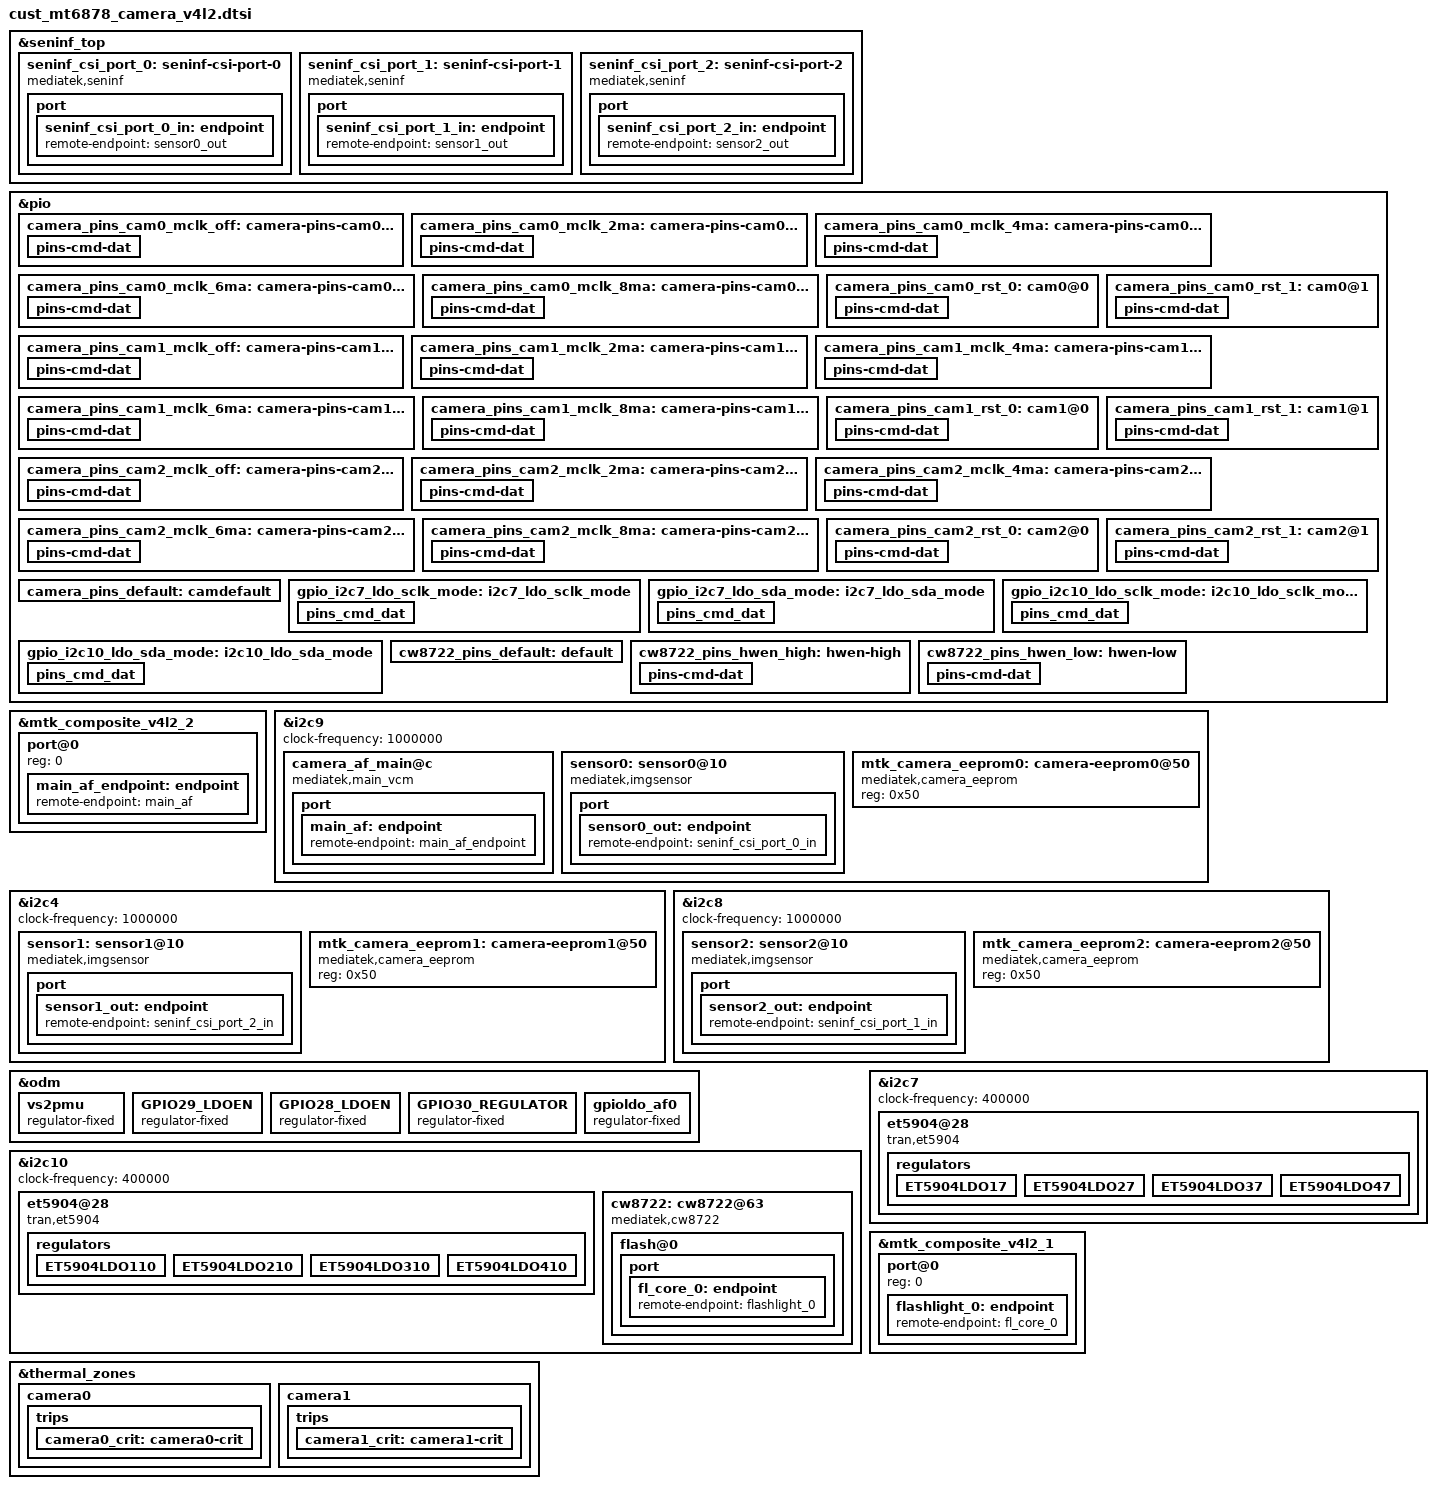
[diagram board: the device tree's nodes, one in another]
// SPDX-License-Identifier: GPL-2.0
/* Copyright (c) 2020 MediaTek Inc. */
#include <dt-bindings/clock/mt6878-clk.h>

&seninf_top {
		seninf_csi_port_0: seninf-csi-port-0 {
			compatible = "mediatek,seninf";
			csi-port = "0";
			dphy-settle-delay-dt = <17>;
			nvmem-cells = <&csi_efuse0>;
			nvmem-cell-names = "rg_csi";
			port {
				seninf_csi_port_0_in: endpoint {
					remote-endpoint = <&sensor0_out>;
				};
			};
		};

		seninf_csi_port_1: seninf-csi-port-1 {
			compatible = "mediatek,seninf";
			csi-port = "2";
			hs-trail-parameter = <0x20>;
			nvmem-cells = <&csi_efuse1>;
			nvmem-cell-names = "rg_csi";
			port {
				seninf_csi_port_1_in: endpoint {
					remote-endpoint = <&sensor1_out>;
				};
			};
		};
		seninf_csi_port_2: seninf-csi-port-2 {
			compatible = "mediatek,seninf";
			csi-port = "1";
			hs-trail-parameter = <0x20>;
			nvmem-cells = <&csi_efuse2>;
			nvmem-cell-names = "rg_csi";
			port {
				seninf_csi_port_2_in: endpoint {
					remote-endpoint = <&sensor2_out>;
				};
			};
		};
};


/* CAMERA GPIO standardization */
&pio {
	camera_pins_cam0_mclk_off: camera-pins-cam0-mclk-off {
		pins-cmd-dat {
			pinmux = <PINMUX_GPIO93__FUNC_GPIO93>;
			drive-strength = <1>;
		};
	};
	camera_pins_cam0_mclk_2ma: camera-pins-cam0-mclk-2ma {
		pins-cmd-dat {
			pinmux = <PINMUX_GPIO93__FUNC_CMMCLK1>;
			drive-strength = <0>;
		};
	};
	camera_pins_cam0_mclk_4ma: camera-pins-cam0-mclk-4ma {
		pins-cmd-dat {
			pinmux = <PINMUX_GPIO93__FUNC_CMMCLK1>;
			drive-strength = <1>;
		};
	};
	camera_pins_cam0_mclk_6ma: camera-pins-cam0-mclk-6ma {
		pins-cmd-dat {
			pinmux = <PINMUX_GPIO93__FUNC_CMMCLK1>;
			drive-strength = <2>;
		};
	};
	camera_pins_cam0_mclk_8ma: camera-pins-cam0-mclk-8ma {
		pins-cmd-dat {
			pinmux = <PINMUX_GPIO93__FUNC_CMMCLK1>;
			drive-strength = <3>;
		};
	};
	camera_pins_cam0_rst_0: cam0@0 {
		pins-cmd-dat {
			pinmux = <PINMUX_GPIO25__FUNC_GPIO25>;
			slew-rate = <1>;
			output-low;
		};
	};
	camera_pins_cam0_rst_1: cam0@1 {
		pins-cmd-dat {
			pinmux = <PINMUX_GPIO25__FUNC_GPIO25>;
			slew-rate = <1>;
			output-high;
		};
	};
	
	camera_pins_cam1_mclk_off: camera-pins-cam1-mclk-off {
		pins-cmd-dat {
			pinmux = <PINMUX_GPIO96__FUNC_GPIO96>;
			drive-strength = <1>;
		};
	};
	camera_pins_cam1_mclk_2ma: camera-pins-cam1-mclk-2ma {
		pins-cmd-dat {
			pinmux = <PINMUX_GPIO96__FUNC_CMMCLK4>;
			drive-strength = <0>;
		};
	};
	camera_pins_cam1_mclk_4ma: camera-pins-cam1-mclk-4ma {
		pins-cmd-dat {
			pinmux = <PINMUX_GPIO96__FUNC_CMMCLK4>;
			drive-strength = <1>;
		};
	};
	camera_pins_cam1_mclk_6ma: camera-pins-cam1-mclk-6ma {
		pins-cmd-dat {
			pinmux = <PINMUX_GPIO96__FUNC_CMMCLK4>;
			drive-strength = <2>;
		};
	};
	camera_pins_cam1_mclk_8ma: camera-pins-cam1-mclk-8ma {
		pins-cmd-dat {
			pinmux = <PINMUX_GPIO96__FUNC_CMMCLK4>;
			drive-strength = <3>;
		};
	};
	camera_pins_cam1_rst_0: cam1@0 {
		pins-cmd-dat {
			pinmux = <PINMUX_GPIO24__FUNC_GPIO24>;
			slew-rate = <1>;
			output-low;
		};
	};
	camera_pins_cam1_rst_1: cam1@1 {
		pins-cmd-dat {
			pinmux = <PINMUX_GPIO24__FUNC_GPIO24>;
			slew-rate = <1>;
			output-high;
		};
	};
	camera_pins_cam2_mclk_off: camera-pins-cam2-mclk-off {
		pins-cmd-dat {
			pinmux = <PINMUX_GPIO94__FUNC_GPIO94>;
			drive-strength = <1>;
		};
	};
	camera_pins_cam2_mclk_2ma: camera-pins-cam2-mclk-2ma {
		pins-cmd-dat {
			pinmux = <PINMUX_GPIO94__FUNC_CMMCLK2>;
			drive-strength = <0>;
		};
	};
	camera_pins_cam2_mclk_4ma: camera-pins-cam2-mclk-4ma {
		pins-cmd-dat {
			pinmux = <PINMUX_GPIO94__FUNC_CMMCLK2>;
			drive-strength = <1>;
		};
	};
	camera_pins_cam2_mclk_6ma: camera-pins-cam2-mclk-6ma {
		pins-cmd-dat {
			pinmux = <PINMUX_GPIO94__FUNC_CMMCLK2>;
			drive-strength = <2>;
		};
	};
	camera_pins_cam2_mclk_8ma: camera-pins-cam2-mclk-8ma {
		pins-cmd-dat {
			pinmux = <PINMUX_GPIO94__FUNC_CMMCLK2>;
			drive-strength = <3>;
		};
	};
	camera_pins_cam2_rst_0: cam2@0 {
		pins-cmd-dat {
			pinmux = <PINMUX_GPIO26__FUNC_GPIO26>;
			slew-rate = <1>;
			output-low;
		};
	};
	camera_pins_cam2_rst_1: cam2@1 {
		pins-cmd-dat {
			pinmux = <PINMUX_GPIO26__FUNC_GPIO26>;
			slew-rate = <1>;
			output-high;
		};
	};

	camera_pins_default: camdefault {
	};
};
/* CAMERA GPIO end */

&mtk_composite_v4l2_2 {
	#address-cells = <1>;
	#size-cells = <0>;
	port@0 {
		reg = <0>;
		main_af_endpoint: endpoint {
			remote-endpoint = <&main_af>;
		};
	};
};

&i2c9 {
	status = "okay";
	clock-frequency = <1000000>;

	camera_af_main@c {
		compatible = "mediatek,main_vcm";
		reg = <0x0c>;
		vin-supply = <&gpioldo_af0>;
		port {
			main_af: endpoint {
				remote-endpoint = <&main_af_endpoint>;
			};
		};
	};

	sensor0: sensor0@10 {
		compatible = "mediatek,imgsensor";
		sensor-names = "imx682_mipi_raw";
		reg = <0x10>;
		#thermal-sensor-cells = <0>;
		sensor-matecodes = "imx682_17201926";
		pinctrl-names = "mclk_off",
				"mclk_2mA",
				"mclk_4mA",
				"mclk_6mA",
				"mclk_8mA",
				"rst_low",
				"rst_high";

		pinctrl-0 = <&camera_pins_cam0_mclk_off>;
		pinctrl-1 = <&camera_pins_cam0_mclk_2ma>;
		pinctrl-2 = <&camera_pins_cam0_mclk_4ma>;
		pinctrl-3 = <&camera_pins_cam0_mclk_6ma>;
		pinctrl-4 = <&camera_pins_cam0_mclk_8ma>;
		pinctrl-5 = <&camera_pins_cam0_rst_0>;
		pinctrl-6 = <&camera_pins_cam0_rst_1>;

		avdd-supply = <&ET5904LDO410>;
		dvdd-supply = <&ET5904LDO210>;
		dovdd-supply = <&mt6369_vant18>;
		avdd1-supply =<&GPIO30_REGULATOR>;

		clocks = <&topckgen_clk CLK_TOP_UVPLL192M_D32>,
			<&topckgen_clk CLK_TOP_UVPLL192M_D16>,
			<&topckgen_clk CLK_TOP_OSC_D20>,
			<&topckgen_clk CLK_TOP_UVPLL192M_D10>,
			<&topckgen_clk CLK_TOP_UVPLL192M_D8>,
			<&topckgen_clk CLK_TOP_TCK_26M_MX9>,
			<&topckgen_clk CLK_TOP_UNIVPLL_D6_D8>,
			<&topckgen_clk CLK_TOP_CAMTG2_SEL>;
		clock-names = "6", "12", "13", "19.2", "24", "26", "52", "mclk";


		status = "okay";
		port {
			sensor0_out: endpoint {
				remote-endpoint = <&seninf_csi_port_0_in>;
			};
		};
	};

	mtk_camera_eeprom0:camera-eeprom0@50 {
		compatible = "mediatek,camera_eeprom";
		reg = <0x50>;
		status = "okay";
	};
};
&pio {
	gpio_i2c7_ldo_sclk_mode: i2c7_ldo_sclk_mode {
		pins_cmd_dat {
			pinmux = <PINMUX_GPIO139__FUNC_SCL7>;
			drive-strength = <4>;
		};
	};

	gpio_i2c7_ldo_sda_mode: i2c7_ldo_sda_mode {
		pins_cmd_dat {
			pinmux = <PINMUX_GPIO140__FUNC_SDA7>;
			drive-strength = <4>;
		};
	};
	gpio_i2c10_ldo_sclk_mode: i2c10_ldo_sclk_mode {
		pins_cmd_dat {
			pinmux = <PINMUX_GPIO145__FUNC_SCL10>;
			drive-strength = <4>;
		};
	};

	gpio_i2c10_ldo_sda_mode: i2c10_ldo_sda_mode {
		pins_cmd_dat {
			pinmux = <PINMUX_GPIO146__FUNC_SDA10>;
			drive-strength = <4>;
		};
	};
};

&i2c4 {
	status = "okay";
	clock-frequency = <1000000>;

	sensor1: sensor1@10 {
		compatible = "mediatek,imgsensor";
		sensor-names = "gc13a0ff_mipi_raw";
		reg = <0x10>;
		sensor-matecodes = "gc13a0_17201930";
		#thermal-sensor-cells = <0>;

		pinctrl-names = "mclk_off",
				"mclk_2mA",
				"mclk_4mA",
				"mclk_6mA",
				"mclk_8mA",
				"rst_low",
				"rst_high";
		pinctrl-0 = <&camera_pins_cam1_mclk_off>;
		pinctrl-1 = <&camera_pins_cam1_mclk_2ma>;
		pinctrl-2 = <&camera_pins_cam1_mclk_4ma>;
		pinctrl-3 = <&camera_pins_cam1_mclk_6ma>;
		pinctrl-4 = <&camera_pins_cam1_mclk_8ma>;
		pinctrl-5 = <&camera_pins_cam1_rst_0>;
		pinctrl-6 = <&camera_pins_cam1_rst_1>;

		avdd-supply = <&ET5904LDO310>;
		dvdd-supply = <&ET5904LDO110>;
		dovdd-supply = <&mt6369_vant18>;

		clocks = <&topckgen_clk CLK_TOP_UVPLL192M_D32>,
			<&topckgen_clk CLK_TOP_UVPLL192M_D16>,
			<&topckgen_clk CLK_TOP_OSC_D20>,
			<&topckgen_clk CLK_TOP_UVPLL192M_D10>,
			<&topckgen_clk CLK_TOP_UVPLL192M_D8>,
			<&topckgen_clk CLK_TOP_TCK_26M_MX9>,
			<&topckgen_clk CLK_TOP_UNIVPLL_D6_D8>,
			<&topckgen_clk CLK_TOP_CAMTG5_SEL>;
		clock-names = "6", "12", "13", "19.2", "24", "26", "52", "mclk";

		status = "okay";
		port {
			sensor1_out: endpoint {
				remote-endpoint = <&seninf_csi_port_2_in>;
			};
		};
	};

	mtk_camera_eeprom1:camera-eeprom1@50 {
		compatible = "mediatek,camera_eeprom";
		reg = <0x50>;
		status = "okay";
	};
};

&i2c8 {
	status = "okay";
	clock-frequency = <1000000>;
	#address-cells = <1>;
	#size-cells = <0>;

	sensor2: sensor2@10 {
		compatible = "mediatek,imgsensor";
		sensor-names = "gc02m3macro_mipi_raw";
		sensor-matecodes = "gc02m3_17201867";
		reg = <0x10>;
		#thermal-sensor-cells = <0>;

		pinctrl-names = "mclk_off",
				"mclk_2mA",
				"mclk_4mA",
				"mclk_6mA",
				"mclk_8mA",
				"rst_low",
				"rst_high";
		pinctrl-0 = <&camera_pins_cam2_mclk_off>;
		pinctrl-1 = <&camera_pins_cam2_mclk_2ma>;
		pinctrl-2 = <&camera_pins_cam2_mclk_4ma>;
		pinctrl-3 = <&camera_pins_cam2_mclk_6ma>;
		pinctrl-4 = <&camera_pins_cam2_mclk_8ma>;
		pinctrl-5 = <&camera_pins_cam2_rst_0>;
		pinctrl-6 = <&camera_pins_cam2_rst_1>;

		avdd-supply = <&ET5904LDO37>;
		dovdd-supply = <&mt6369_vant18>;

		clocks = <&topckgen_clk CLK_TOP_UVPLL192M_D32>,
			<&topckgen_clk CLK_TOP_UVPLL192M_D16>,
			<&topckgen_clk CLK_TOP_OSC_D20>,
			<&topckgen_clk CLK_TOP_UVPLL192M_D10>,
			<&topckgen_clk CLK_TOP_UVPLL192M_D8>,
			<&topckgen_clk CLK_TOP_TCK_26M_MX9>,
			<&topckgen_clk CLK_TOP_UNIVPLL_D6_D8>,
			<&topckgen_clk CLK_TOP_CAMTG3_SEL>;
		clock-names = "6", "12", "13", "19.2", "24", "26", "52", "mclk";

		status = "okay";

		port {
			sensor2_out: endpoint {
				remote-endpoint = <&seninf_csi_port_1_in>;
			};
		};
	};

	mtk_camera_eeprom2:camera-eeprom2@50 {
		compatible = "mediatek,camera_eeprom";
		reg = <0x50>;
		status = "okay";
	};
};

&odm {
    vs2pmu: vs2pmu {
      compatible = "regulator-fixed";
      regulator-name = "vs2pmu";
      regulator-min-microvolt = <1800000>;
      regulator-max-microvolt = <1800000>;
      gpio = <&pio 41 0x0>;
      enable-active-high;
      regulator-always-on;
      regulator-boot-on;
    };

    GPIO29_LDOEN: GPIO29_LDOEN {
      compatible = "regulator-fixed";
      regulator-name = "gpio29ldoen";
      regulator-min-microvolt = <1800000>;
      regulator-max-microvolt = <1800000>;
      gpio = <&pio 29 0x0>;
      enable-active-low;
      regulator-always-on;
      regulator-boot-on;
    };
	
    GPIO28_LDOEN: GPIO28_LDOEN {
      compatible = "regulator-fixed";
      regulator-name = "gpio28ldoen";
      regulator-min-microvolt = <1800000>;
      regulator-max-microvolt = <1800000>;
      gpio = <&pio 28 0x0>;
      enable-active-low;
      regulator-always-on;
      regulator-boot-on;
    };

    GPIO30_REGULATOR: GPIO30_REGULATOR {
      compatible = "regulator-fixed";
      regulator-name = "gpio30_regulator";
      regulator-min-microvolt = <1800000>;
      regulator-max-microvolt = <1800000>;
      gpio = <&pio 30 0x0>;
      enable-active-high;
    };
	
    gpioldo_af0: gpioldo_af0 {
      compatible = "regulator-fixed";
      regulator-name = "gpioldo_af0";
      regulator-min-microvolt = <2800000>;
      regulator-max-microvolt = <2800000>;
      gpio = <&pio 57 0x0>;
      enable-active-high;
    };

};

&i2c10 {
    status = "okay";
    clock-frequency = <400000>;
    #address-cells = <1>;
    #size-cells = <0>;

    et5904@28 {
        compatible = "tran,et5904";
        pinctrl-names = "i2c10_ldo_sclk_mode", "i2c10_ldo_sda_mode";
        pinctrl-0 = <&gpio_i2c10_ldo_sclk_mode>;
        pinctrl-1 = <&gpio_i2c10_ldo_sda_mode>;
        reg = <0x28>;
        VIND-supply = <&vs2pmu>;
        regulators {
            ET5904LDO110:ET5904LDO110 {
                regulator-name = "ET5904LDO110";
                regulator-min-microvolt = <600000>;
                regulator-max-microvolt = <1800000>;
            };
            ET5904LDO210:ET5904LDO210 {
                regulator-name = "ET5904LDO210";
                regulator-min-microvolt = <600000>;
                regulator-max-microvolt = <1800000>;
            };
            ET5904LDO310:ET5904LDO310 {
                regulator-name = "ET5904LDO310";
                regulator-min-microvolt = <1200000>;
                regulator-max-microvolt = <3300000>;
            };
            ET5904LDO410:ET5904LDO410 {
                regulator-name = "ET5904LDO410";
                regulator-min-microvolt = <1200000>;
                regulator-max-microvolt = <3300000>;
            };
        };
   };
};

&i2c7 {
    status = "okay";
    clock-frequency = <400000>;
    #address-cells = <1>;
    #size-cells = <0>;

    et5904@28 {
        compatible = "tran,et5904";
        pinctrl-names = "i2c7_ldo_sclk_mode", "i2c7_ldo_sda_mode";
        pinctrl-0 = <&gpio_i2c7_ldo_sclk_mode>;
        pinctrl-1 = <&gpio_i2c7_ldo_sda_mode>;
        reg = <0x28>;
        VIND-supply = <&mt6363_vs2>;
        regulators {
            ET5904LDO17:ET5904LDO17 {
                regulator-name = "ET5904LDO17";
                regulator-min-microvolt = <600000>;
                regulator-max-microvolt = <1800000>;
            };
            ET5904LDO27:ET5904LDO27 {
                regulator-name = "ET5904LDO27";
                regulator-min-microvolt = <600000>;
                regulator-max-microvolt = <1800000>;
            };
            ET5904LDO37:ET5904LDO37 {
                regulator-name = "ET5904LDO37";
                regulator-min-microvolt = <1200000>;
                regulator-max-microvolt = <3300000>;
            };
            ET5904LDO47:ET5904LDO47 {
                regulator-name = "ET5904LDO47";
                regulator-min-microvolt = <1200000>;
                regulator-max-microvolt = <3300000>;
            };
        };
   };
};
&i2c10 {
	#address-cells = <1>;
	#size-cells = <0>;
	cw8722:cw8722@63 {
		compatible = "mediatek,cw8722";
		#address-cells = <1>;
		#size-cells = <0>;
		reg = <0x63>;
		flashledno = <1>;
		#cooling-cells = <2>;
		pinctrl-names = "default", "hwen_high", "hwen_low";
		pinctrl-0 = <&cw8722_pins_default>;
		pinctrl-1 = <&cw8722_pins_hwen_high>;
		pinctrl-2 = <&cw8722_pins_hwen_low>;
		status = "okay";
		flash@0{
			reg = <1>;
			type = <0>;
			ct = <0>;
			part = <0>;
			port {
				fl_core_0: endpoint {
					remote-endpoint = <&flashlight_0>;
				};
			};
		};
	};
};


&pio {
	cw8722_pins_default: default {
	};
	cw8722_pins_hwen_high: hwen-high {
		pins-cmd-dat {
			pinmux = <PINMUX_GPIO153__FUNC_GPIO153>;
			slew-rate = <1>;
			output-high;
		};
	};
	cw8722_pins_hwen_low: hwen-low {
		pins-cmd-dat {
			pinmux = <PINMUX_GPIO153__FUNC_GPIO153>;
			slew-rate = <1>;
			output-low;
		};
	};
};


&mtk_composite_v4l2_1 {
	#address-cells = <1>;
	#size-cells = <0>;
	port@0 {
		reg = <0>;
		flashlight_0: endpoint {
			remote-endpoint = <&fl_core_0>;
		};
	};
};

&thermal_zones {
	camera0: camera0 {
		polling-delay = <0>; /* milliseconds */
		polling-delay-passive = <0>; /* milliseconds */
		thermal-sensors = <&sensor0>;
		trips {
			camera0_crit: camera0-crit {
				temperature = <120000>;
				hysteresis = <2000>;
				type = "passive";
			};
		};
	};
	camera1: camera1 {
		polling-delay = <0>; /* milliseconds */
		polling-delay-passive = <0>; /* milliseconds */
		thermal-sensors = <&sensor1>;
		trips {
			camera1_crit: camera1-crit {
				temperature = <120000>;
				hysteresis = <2000>;
				type = "passive";
			};
		};
	};
};

